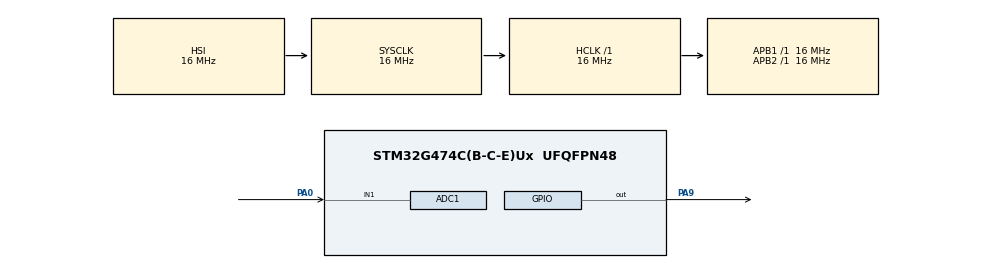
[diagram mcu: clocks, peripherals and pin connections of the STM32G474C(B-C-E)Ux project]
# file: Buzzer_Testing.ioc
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ADC1.Channel-0\#ChannelRegularConversion=ADC_CHANNEL_1
ADC1.NbrOfConversionFlag=1
ADC1.OffsetNumber-0\#ChannelRegularConversion=ADC_OFFSET_NONE
ADC1.Rank-0\#ChannelRegularConversion=1
ADC1.SamplingTime-0\#ChannelRegularConversion=ADC_SAMPLETIME_2CYCLES_5
ADC1.master=1
Mcu.Family=STM32G4
Mcu.Name=STM32G474C(B-C-E)Ux
Mcu.Package=UFQFPN48
NVIC.PriorityGroup=NVIC_PRIORITYGROUP_4
PA0.Mode=IN1-Single-Ended
PA0.Signal=ADC1_IN1
PA9.Signal=GPIO_Output
ProjectManager.HeapSize=0x200
ProjectManager.StackSize=0x400
ProjectManager.TargetToolchain=STM32CubeIDE
RCC.AHBFreq_Value=16000000
RCC.APB1Freq_Value=16000000
RCC.APB1TimFreq_Value=16000000
RCC.APB2Freq_Value=16000000
RCC.APB2TimFreq_Value=16000000
RCC.CortexFreq_Value=16000000
RCC.EXTERNAL_CLOCK_VALUE=12288000
RCC.HCLKFreq_Value=16000000
RCC.HSE_VALUE=8000000
RCC.HSI48_VALUE=48000000
RCC.HSI_VALUE=16000000
RCC.LSE_VALUE=32768
RCC.SYSCLKFreq_VALUE=16000000
RCC.USBFreq_Value=64000000
RCC.VCOOutputFreq_Value=128000000
VP_SYS_VS_DBSignals.Mode=DisableDeadBatterySignals
board=custom

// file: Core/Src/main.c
/* USER CODE BEGIN Header */
/**
  ******************************************************************************
  * @file           : main.c
  * @brief          : Main program body
  ******************************************************************************
  * @attention
  *
  * Copyright (c) 2026 STMicroelectronics.
  * All rights reserved.
  *
  * This software is licensed under terms that can be found in the LICENSE file
  * in the root directory of this software component.
  * If no LICENSE file comes with this software, it is provided AS-IS.
  *
  ******************************************************************************
  */
/* USER CODE END Header */
#include "main.h"

/* USER CODE BEGIN Includes */
#include "stdbool.h"
/* USER CODE END Includes */

ADC_HandleTypeDef hadc1;

/* USER CODE BEGIN PV */
//#define ADC_THRESHOLD 2048 // anything between 0-4095
#define ADC_HIGH 2500
#define ADC_LOW  1500
/* USER CODE END PV */

void SystemClock_Config(void);
static void MX_GPIO_Init(void);
static void MX_ADC1_Init(void);

/* USER CODE BEGIN 0 */
uint32_t read_adc_avg(void)
{
    uint32_t sum = 0;

    for(int i = 0; i < 8; i++)
    {
        HAL_ADC_Start(&hadc1);
        HAL_ADC_PollForConversion(&hadc1, HAL_MAX_DELAY);
        sum += HAL_ADC_GetValue(&hadc1);
        HAL_ADC_Stop(&hadc1);
    }

    return sum / 8;
}
/* USER CODE END 0 */

int main(void)
{

  /* MCU Configuration--------------------------------------------------------*/

  /* Reset of all peripherals, Initializes the Flash interface and the Systick. */
  HAL_Init();

  /* Configure the system clock */
  SystemClock_Config();

  /* Initialize all configured peripherals */
  MX_GPIO_Init();
  MX_ADC1_Init();
  /* USER CODE BEGIN 2 */
  volatile bool buzzer_triggered = false;
  /* USER CODE END 2 */

  /* Infinite loop */
  /* USER CODE BEGIN WHILE */
  while (1) {
      uint32_t adc_val = read_adc_avg();

      if(adc_val > ADC_HIGH && !buzzer_triggered)
      {
          HAL_GPIO_WritePin(GPIOA, GPIO_PIN_9, GPIO_PIN_SET);
          HAL_Delay(2000);
          HAL_GPIO_WritePin(GPIOA, GPIO_PIN_9, GPIO_PIN_RESET);

          buzzer_triggered = true;
      }

      if(adc_val < ADC_LOW)
      {
          buzzer_triggered = false;
      }

      HAL_Delay(50);

//	  HAL_Delay(1000);
    /* USER CODE END WHILE */

  }
}

void SystemClock_Config(void)
{
  RCC_OscInitTypeDef RCC_OscInitStruct = {0};
  RCC_ClkInitTypeDef RCC_ClkInitStruct = {0};

  /** Configure the main internal regulator output voltage
  */
  HAL_PWREx_ControlVoltageScaling(PWR_REGULATOR_VOLTAGE_SCALE1);

  /** Initializes the RCC Oscillators according to the specified parameters
  * in the RCC_OscInitTypeDef structure.
  */
  RCC_OscInitStruct.OscillatorType = RCC_OSCILLATORTYPE_HSI;
  RCC_OscInitStruct.HSIState = RCC_HSI_ON;
  RCC_OscInitStruct.HSICalibrationValue = RCC_HSICALIBRATION_DEFAULT;
  RCC_OscInitStruct.PLL.PLLState = RCC_PLL_NONE;
  if (HAL_RCC_OscConfig(&RCC_OscInitStruct) != HAL_OK)
  {
    Error_Handler();
  }

  /** Initializes the CPU, AHB and APB buses clocks
  */
  RCC_ClkInitStruct.ClockType = RCC_CLOCKTYPE_HCLK|RCC_CLOCKTYPE_SYSCLK
                              |RCC_CLOCKTYPE_PCLK1|RCC_CLOCKTYPE_PCLK2;
  RCC_ClkInitStruct.SYSCLKSource = RCC_SYSCLKSOURCE_HSI;
  RCC_ClkInitStruct.AHBCLKDivider = RCC_SYSCLK_DIV1;
  RCC_ClkInitStruct.APB1CLKDivider = RCC_HCLK_DIV1;
  RCC_ClkInitStruct.APB2CLKDivider = RCC_HCLK_DIV1;

  if (HAL_RCC_ClockConfig(&RCC_ClkInitStruct, FLASH_LATENCY_0) != HAL_OK)
  {
    Error_Handler();
  }
}

static void MX_ADC1_Init(void)
{

  ADC_MultiModeTypeDef multimode = {0};
  ADC_ChannelConfTypeDef sConfig = {0};

  /** Common config
  */
  hadc1.Instance = ADC1;
  hadc1.Init.ClockPrescaler = ADC_CLOCK_SYNC_PCLK_DIV2;
  hadc1.Init.Resolution = ADC_RESOLUTION_12B;
  hadc1.Init.DataAlign = ADC_DATAALIGN_RIGHT;
  hadc1.Init.GainCompensation = 0;
  hadc1.Init.ScanConvMode = ADC_SCAN_DISABLE;
  hadc1.Init.EOCSelection = ADC_EOC_SINGLE_CONV;
  hadc1.Init.LowPowerAutoWait = DISABLE;
  hadc1.Init.ContinuousConvMode = DISABLE;
  hadc1.Init.NbrOfConversion = 1;
  hadc1.Init.DiscontinuousConvMode = DISABLE;
  hadc1.Init.ExternalTrigConv = ADC_SOFTWARE_START;
  hadc1.Init.ExternalTrigConvEdge = ADC_EXTERNALTRIGCONVEDGE_NONE;
  hadc1.Init.DMAContinuousRequests = DISABLE;
  hadc1.Init.Overrun = ADC_OVR_DATA_PRESERVED;
  hadc1.Init.OversamplingMode = DISABLE;
  if (HAL_ADC_Init(&hadc1) != HAL_OK)
  {
    Error_Handler();
  }

  /** Configure the ADC multi-mode
  */
  multimode.Mode = ADC_MODE_INDEPENDENT;
  if (HAL_ADCEx_MultiModeConfigChannel(&hadc1, &multimode) != HAL_OK)
  {
    Error_Handler();
  }

  /** Configure Regular Channel
  */
  sConfig.Channel = ADC_CHANNEL_1;
  sConfig.Rank = ADC_REGULAR_RANK_1;
  sConfig.SamplingTime = ADC_SAMPLETIME_2CYCLES_5;
  sConfig.SingleDiff = ADC_SINGLE_ENDED;
  sConfig.OffsetNumber = ADC_OFFSET_NONE;
  sConfig.Offset = 0;
  if (HAL_ADC_ConfigChannel(&hadc1, &sConfig) != HAL_OK)
  {
    Error_Handler();
  }

}

static void MX_GPIO_Init(void)
{
  GPIO_InitTypeDef GPIO_InitStruct = {0};

  /* GPIO Ports Clock Enable */
  __HAL_RCC_GPIOA_CLK_ENABLE();

  /*Configure GPIO pin Output Level */
  HAL_GPIO_WritePin(GPIOA, GPIO_PIN_9, GPIO_PIN_RESET);

  /*Configure GPIO pin : PA9 */
  GPIO_InitStruct.Pin = GPIO_PIN_9;
  GPIO_InitStruct.Mode = GPIO_MODE_OUTPUT_PP;
  GPIO_InitStruct.Pull = GPIO_NOPULL;
  GPIO_InitStruct.Speed = GPIO_SPEED_FREQ_LOW;
  HAL_GPIO_Init(GPIOA, &GPIO_InitStruct);

}

void Error_Handler(void)
{
  __disable_irq();
  while (1)
  {
  }
}
